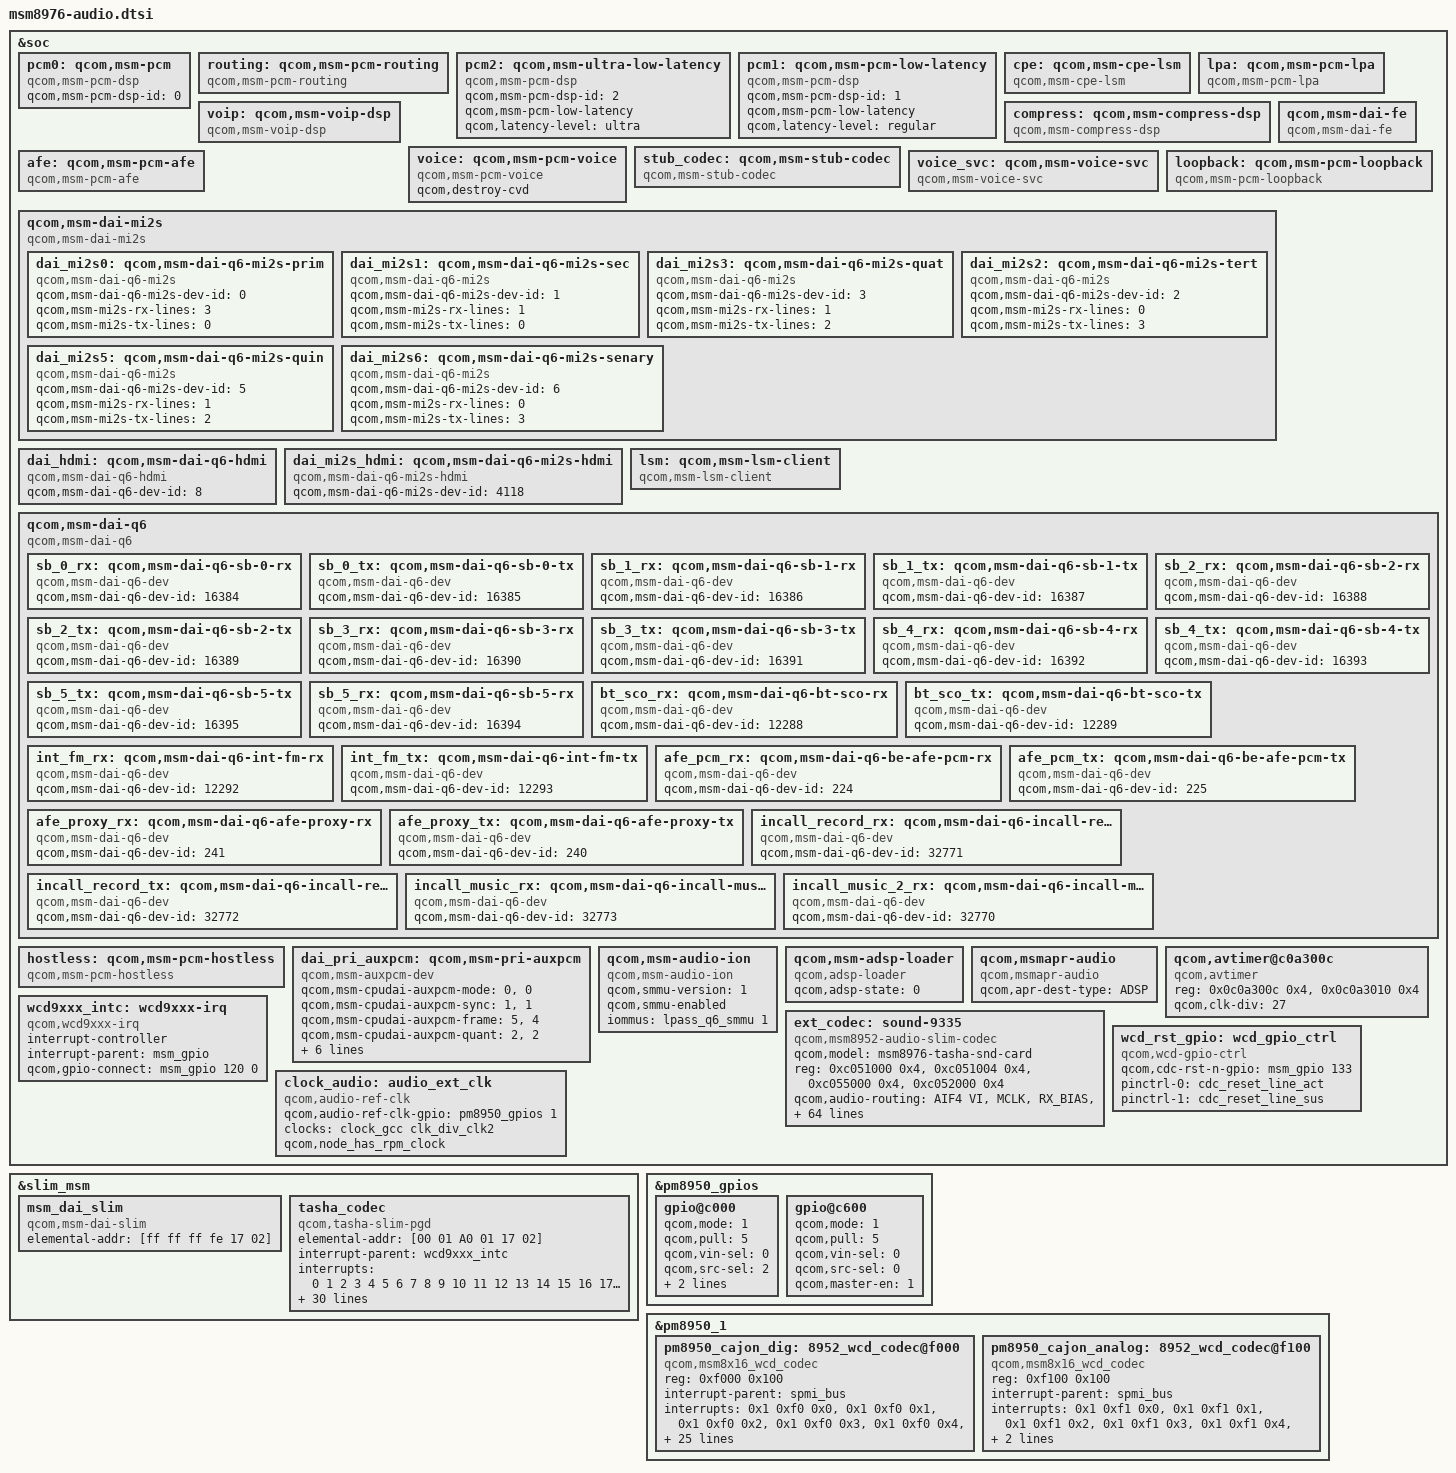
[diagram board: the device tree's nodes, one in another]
/*
 * Copyright (c) 2015-2016, The Linux Foundation. All rights reserved.
 *
 * This program is free software; you can redistribute it and/or modify
 * it under the terms of the GNU General Public License version 2 and
 * only version 2 as published by the Free Software Foundation.
 *
 * This program is distributed in the hope that it will be useful,
 * but WITHOUT ANY WARRANTY; without even the implied warranty of
 * MERCHANTABILITY or FITNESS FOR A PARTICULAR PURPOSE.  See the
 * GNU General Public License for more details.
 */

#include "msm8976-wsa881x.dtsi"

&soc {
	pcm0: qcom,msm-pcm {
		compatible = "qcom,msm-pcm-dsp";
		qcom,msm-pcm-dsp-id = <0>;
	};

	routing: qcom,msm-pcm-routing {
		compatible = "qcom,msm-pcm-routing";
	};

	pcm2: qcom,msm-ultra-low-latency {
		compatible = "qcom,msm-pcm-dsp";
		qcom,msm-pcm-dsp-id = <2>;
		qcom,msm-pcm-low-latency;
		qcom,latency-level = "ultra";
	};

	pcm1: qcom,msm-pcm-low-latency {
		compatible = "qcom,msm-pcm-dsp";
		qcom,msm-pcm-dsp-id = <1>;
		qcom,msm-pcm-low-latency;
		qcom,latency-level = "regular";
	};

	pcm2: qcom,msm-ultra-low-latency {
		compatible = "qcom,msm-pcm-dsp";
		qcom,msm-pcm-dsp-id = <2>;
		qcom,msm-pcm-low-latency;
		qcom,latency-level = "ultra";
	};

	cpe: qcom,msm-cpe-lsm {
		compatible = "qcom,msm-cpe-lsm";
	};

	lpa: qcom,msm-pcm-lpa {
		compatible = "qcom,msm-pcm-lpa";
	};

	compress: qcom,msm-compress-dsp {
		compatible = "qcom,msm-compress-dsp";
	};

	voip: qcom,msm-voip-dsp {
		compatible = "qcom,msm-voip-dsp";
	};

	voice: qcom,msm-pcm-voice {
		compatible = "qcom,msm-pcm-voice";
		qcom,destroy-cvd;
	};

	stub_codec: qcom,msm-stub-codec {
		compatible = "qcom,msm-stub-codec";
	};

	qcom,msm-dai-fe {
		compatible = "qcom,msm-dai-fe";
	};

	afe: qcom,msm-pcm-afe {
		compatible = "qcom,msm-pcm-afe";
	};

	voice_svc: qcom,msm-voice-svc {
		compatible = "qcom,msm-voice-svc";
	};

	loopback: qcom,msm-pcm-loopback {
		compatible = "qcom,msm-pcm-loopback";
	};

	qcom,msm-dai-mi2s {
		compatible = "qcom,msm-dai-mi2s";
		dai_mi2s0: qcom,msm-dai-q6-mi2s-prim {
			compatible = "qcom,msm-dai-q6-mi2s";
			qcom,msm-dai-q6-mi2s-dev-id = <0>;
			qcom,msm-mi2s-rx-lines = <3>;
			qcom,msm-mi2s-tx-lines = <0>;
		};

		dai_mi2s1: qcom,msm-dai-q6-mi2s-sec {
			compatible = "qcom,msm-dai-q6-mi2s";
			qcom,msm-dai-q6-mi2s-dev-id = <1>;
			qcom,msm-mi2s-rx-lines = <1>;
			qcom,msm-mi2s-tx-lines = <0>;
		};

		dai_mi2s3: qcom,msm-dai-q6-mi2s-quat {
			compatible = "qcom,msm-dai-q6-mi2s";
			qcom,msm-dai-q6-mi2s-dev-id = <3>;
			qcom,msm-mi2s-rx-lines = <1>;
			qcom,msm-mi2s-tx-lines = <2>;
		};

		dai_mi2s2: qcom,msm-dai-q6-mi2s-tert {
			compatible = "qcom,msm-dai-q6-mi2s";
			qcom,msm-dai-q6-mi2s-dev-id = <2>;
			qcom,msm-mi2s-rx-lines = <0>;
			qcom,msm-mi2s-tx-lines = <3>;
		};

		dai_mi2s5: qcom,msm-dai-q6-mi2s-quin {
			compatible = "qcom,msm-dai-q6-mi2s";
			qcom,msm-dai-q6-mi2s-dev-id = <5>;
			qcom,msm-mi2s-rx-lines = <1>;
			qcom,msm-mi2s-tx-lines = <2>;
		};

		dai_mi2s6: qcom,msm-dai-q6-mi2s-senary {
			compatible = "qcom,msm-dai-q6-mi2s";
			qcom,msm-dai-q6-mi2s-dev-id = <6>;
			qcom,msm-mi2s-rx-lines = <0>;
			qcom,msm-mi2s-tx-lines = <3>;
		};
	};

	dai_hdmi: qcom,msm-dai-q6-hdmi {
		compatible = "qcom,msm-dai-q6-hdmi";
		qcom,msm-dai-q6-dev-id = <8>;
	};

	dai_mi2s_hdmi: qcom,msm-dai-q6-mi2s-hdmi {
		compatible = "qcom,msm-dai-q6-mi2s-hdmi";
		qcom,msm-dai-q6-mi2s-dev-id = <4118>;
	};

	lsm: qcom,msm-lsm-client {
		compatible = "qcom,msm-lsm-client";
	};

	qcom,msm-dai-q6 {
		compatible = "qcom,msm-dai-q6";
		sb_0_rx: qcom,msm-dai-q6-sb-0-rx {
			compatible = "qcom,msm-dai-q6-dev";
			qcom,msm-dai-q6-dev-id = <16384>;
		};

		sb_0_tx: qcom,msm-dai-q6-sb-0-tx {
			compatible = "qcom,msm-dai-q6-dev";
			qcom,msm-dai-q6-dev-id = <16385>;
		};

		sb_1_rx: qcom,msm-dai-q6-sb-1-rx {
			compatible = "qcom,msm-dai-q6-dev";
			qcom,msm-dai-q6-dev-id = <16386>;
		};

		sb_1_tx: qcom,msm-dai-q6-sb-1-tx {
			compatible = "qcom,msm-dai-q6-dev";
			qcom,msm-dai-q6-dev-id = <16387>;
		};

		sb_2_rx: qcom,msm-dai-q6-sb-2-rx {
			compatible = "qcom,msm-dai-q6-dev";
			qcom,msm-dai-q6-dev-id = <16388>;
		};

		sb_2_tx: qcom,msm-dai-q6-sb-2-tx {
			compatible = "qcom,msm-dai-q6-dev";
			qcom,msm-dai-q6-dev-id = <16389>;
		};


		sb_3_rx: qcom,msm-dai-q6-sb-3-rx {
			compatible = "qcom,msm-dai-q6-dev";
			qcom,msm-dai-q6-dev-id = <16390>;
		};

		sb_3_tx: qcom,msm-dai-q6-sb-3-tx {
			compatible = "qcom,msm-dai-q6-dev";
			qcom,msm-dai-q6-dev-id = <16391>;
		};

		sb_4_rx: qcom,msm-dai-q6-sb-4-rx {
			compatible = "qcom,msm-dai-q6-dev";
			qcom,msm-dai-q6-dev-id = <16392>;
		};

		sb_4_tx: qcom,msm-dai-q6-sb-4-tx {
			compatible = "qcom,msm-dai-q6-dev";
			qcom,msm-dai-q6-dev-id = <16393>;
		};

		sb_5_tx: qcom,msm-dai-q6-sb-5-tx {
			compatible = "qcom,msm-dai-q6-dev";
			qcom,msm-dai-q6-dev-id = <16395>;
		};

		sb_5_rx: qcom,msm-dai-q6-sb-5-rx {
			compatible = "qcom,msm-dai-q6-dev";
			qcom,msm-dai-q6-dev-id = <16394>;
		};

		bt_sco_rx: qcom,msm-dai-q6-bt-sco-rx {
			compatible = "qcom,msm-dai-q6-dev";
			qcom,msm-dai-q6-dev-id = <12288>;
		};

		bt_sco_tx: qcom,msm-dai-q6-bt-sco-tx {
			compatible = "qcom,msm-dai-q6-dev";
			qcom,msm-dai-q6-dev-id = <12289>;
		};

		int_fm_rx: qcom,msm-dai-q6-int-fm-rx {
			compatible = "qcom,msm-dai-q6-dev";
			qcom,msm-dai-q6-dev-id = <12292>;
		};

		int_fm_tx: qcom,msm-dai-q6-int-fm-tx {
			compatible = "qcom,msm-dai-q6-dev";
			qcom,msm-dai-q6-dev-id = <12293>;
		};

		afe_pcm_rx: qcom,msm-dai-q6-be-afe-pcm-rx {
			compatible = "qcom,msm-dai-q6-dev";
			qcom,msm-dai-q6-dev-id = <224>;
		};

		afe_pcm_tx: qcom,msm-dai-q6-be-afe-pcm-tx {
			compatible = "qcom,msm-dai-q6-dev";
			qcom,msm-dai-q6-dev-id = <225>;
		};

		afe_proxy_rx: qcom,msm-dai-q6-afe-proxy-rx {
			compatible = "qcom,msm-dai-q6-dev";
			qcom,msm-dai-q6-dev-id = <241>;
		};

		afe_proxy_tx: qcom,msm-dai-q6-afe-proxy-tx {
			compatible = "qcom,msm-dai-q6-dev";
			qcom,msm-dai-q6-dev-id = <240>;
		};

		incall_record_rx: qcom,msm-dai-q6-incall-record-rx {
			compatible = "qcom,msm-dai-q6-dev";
			qcom,msm-dai-q6-dev-id = <32771>;
		};

		incall_record_tx: qcom,msm-dai-q6-incall-record-tx {
			compatible = "qcom,msm-dai-q6-dev";
			qcom,msm-dai-q6-dev-id = <32772>;
		};

		incall_music_rx: qcom,msm-dai-q6-incall-music-rx {
			compatible = "qcom,msm-dai-q6-dev";
			qcom,msm-dai-q6-dev-id = <32773>;
		};

		incall_music_2_rx: qcom,msm-dai-q6-incall-music-2-rx {
			compatible = "qcom,msm-dai-q6-dev";
			qcom,msm-dai-q6-dev-id = <32770>;
		};
	};

	hostless: qcom,msm-pcm-hostless {
		compatible = "qcom,msm-pcm-hostless";
	};

	dai_pri_auxpcm: qcom,msm-pri-auxpcm {
		compatible = "qcom,msm-auxpcm-dev";
		qcom,msm-cpudai-auxpcm-mode = <0>, <0>;
		qcom,msm-cpudai-auxpcm-sync = <1>, <1>;
		qcom,msm-cpudai-auxpcm-frame = <5>, <4>;
		qcom,msm-cpudai-auxpcm-quant = <2>, <2>;
		qcom,msm-cpudai-auxpcm-num-slots = <1>, <1>;
		qcom,msm-cpudai-auxpcm-slot-mapping = <1>, <1>;
		qcom,msm-cpudai-auxpcm-data = <0>, <0>;
		qcom,msm-cpudai-auxpcm-pcm-clk-rate = <2048000>, <2048000>;
		qcom,msm-auxpcm-interface = "primary";
	};

	qcom,msm-audio-ion {
		compatible = "qcom,msm-audio-ion";
		qcom,smmu-version = <1>;
		qcom,smmu-enabled;
		iommus = <&lpass_q6_smmu 1>;
	};

	qcom,msm-adsp-loader {
		compatible = "qcom,adsp-loader";
		qcom,adsp-state = <0>;
	};

	qcom,msmapr-audio {
		compatible = "qcom,msmapr-audio";
		qcom,apr-dest-type = "ADSP";
	};

	qcom,avtimer@c0a300c {
		compatible = "qcom,avtimer";
		reg = <0x0c0a300c 0x4>,
			<0x0c0a3010 0x4>;
		reg-names = "avtimer_lsb_addr", "avtimer_msb_addr";
		qcom,clk-div = <27>;
	};

	ext_codec: sound-9335 {
		compatible = "qcom,msm8952-audio-slim-codec";
		qcom,model = "msm8976-tasha-snd-card";

		reg = <0xc051000 0x4>,
		    <0xc051004 0x4>,
		    <0xc055000 0x4>,
		    <0xc052000 0x4>;

		reg-names = "csr_gp_io_mux_mic_ctl",
			"csr_gp_io_mux_spkr_ctl",
			"csr_gp_io_lpaif_pri_pcm_pri_mode_muxsel",
			"csr_gp_io_mux_quin_ctl";

		qcom,audio-routing =
			"AIF4 VI", "MCLK",
			"RX_BIAS", "MCLK",
			"MADINPUT", "MCLK",
			"AMIC2", "MIC BIAS2",
			"MIC BIAS2", "Headset Mic",
			"AMIC3", "MIC BIAS2",
			"MIC BIAS2", "ANCRight Headset Mic",
			"AMIC4", "MIC BIAS2",
			"MIC BIAS2", "ANCLeft Headset Mic",
			"AMIC5", "MIC BIAS3",
			"MIC BIAS3", "Handset Mic",
			"AMIC6", "MIC BIAS4",
			"MIC BIAS4", "Analog Mic6",
			"DMIC0", "MIC BIAS1",
			"MIC BIAS1", "Digital Mic0",
			"DMIC1", "MIC BIAS1",
			"MIC BIAS1", "Digital Mic1",
			"DMIC2", "MIC BIAS3",
			"MIC BIAS3", "Digital Mic2",
			"DMIC3", "MIC BIAS3",
			"MIC BIAS3", "Digital Mic3",
			"DMIC4", "MIC BIAS4",
			"MIC BIAS4", "Digital Mic4",
			"DMIC5", "MIC BIAS4",
			"MIC BIAS4", "Digital Mic5",
			"SpkrLeft IN", "SPK1 OUT",
			"SpkrRight IN", "SPK2 OUT";

		qcom,msm-gpios =
			"us_eu_gpio";
		qcom,pinctrl-names =
			"all_off",
			"us_eu_gpio_act";
		pinctrl-names =
			"all_off",
			"us_eu_gpio_act";
		pinctrl-0 = <&cross_conn_det_sus>;
		pinctrl-1 = <&cross_conn_det_act>;
		qcom,cdc-us-euro-gpios = <&msm_gpio 144 0>;

		qcom,msm-mbhc-hphl-swh = <0>;
		qcom,msm-mbhc-gnd-swh = <0>;
		qcom,tasha-mclk-clk-freq = <9600000>;
		asoc-platform = <&pcm0>, <&pcm1>, <&pcm2>, <&voip>, <&voice>,
				<&loopback>, <&compress>, <&hostless>,
				<&afe>, <&lsm>, <&routing>, <&cpe>, <&lpa>;
		asoc-platform-names = "msm-pcm-dsp.0", "msm-pcm-dsp.1", "msm-pcm-dsp.2",
				"msm-voip-dsp", "msm-pcm-voice", "msm-pcm-loopback",
				"msm-compress-dsp", "msm-pcm-hostless", "msm-pcm-afe",
				"msm-lsm-client", "msm-pcm-routing", "msm-cpe-lsm",
				"msm-pcm-lpa";
		asoc-cpu = <&dai_pri_auxpcm>, <&dai_hdmi>, <&dai_mi2s_hdmi>,
				<&dai_mi2s2>, <&dai_mi2s3>, <&dai_mi2s5>,
				<&sb_0_rx>, <&sb_0_tx>, <&sb_1_rx>, <&sb_1_tx>,
				<&sb_2_rx>, <&sb_2_tx>, <&sb_3_rx>, <&sb_3_tx>,
				<&sb_4_rx>, <&sb_4_tx>, <&sb_5_tx>, <&afe_pcm_rx>,
				<&afe_pcm_tx>, <&afe_proxy_rx>, <&afe_proxy_tx>,
				<&incall_record_rx>, <&incall_record_tx>,
				<&incall_music_rx>, <&incall_music_2_rx>,
				<&sb_5_rx>,  <&bt_sco_rx>,
				<&bt_sco_tx>, <&int_fm_rx>, <&int_fm_tx>;
		asoc-cpu-names = "msm-dai-q6-auxpcm.1",	"msm-dai-q6-hdmi.8",
				"msm-dai-q6-mi2s-hdmi.4118",
				"msm-dai-q6-mi2s.2",
				"msm-dai-q6-mi2s.3", "msm-dai-q6-mi2s.5",
				"msm-dai-q6-dev.16384", "msm-dai-q6-dev.16385",
				"msm-dai-q6-dev.16386", "msm-dai-q6-dev.16387",
				"msm-dai-q6-dev.16388", "msm-dai-q6-dev.16389",
				"msm-dai-q6-dev.16390", "msm-dai-q6-dev.16391",
				"msm-dai-q6-dev.16392", "msm-dai-q6-dev.16393",
				"msm-dai-q6-dev.16395", "msm-dai-q6-dev.224",
				"msm-dai-q6-dev.225", "msm-dai-q6-dev.241",
				"msm-dai-q6-dev.240", "msm-dai-q6-dev.32771",
				"msm-dai-q6-dev.32772", "msm-dai-q6-dev.32773",
				"msm-dai-q6-dev.32770", "msm-dai-q6-dev.16394",
				"msm-dai-q6-dev.12288", "msm-dai-q6-dev.12289",
				"msm-dai-q6-dev.12292", "msm-dai-q6-dev.12293";
		asoc-codec = <&stub_codec>;
		asoc-codec-names = "msm-stub-codec.1";
		qcom,wsa-max-devs = <2>;
		qcom,wsa-devs = <&wsa881x_211>, <&wsa881x_212>,
				<&wsa881x_213>, <&wsa881x_214>;
		qcom,wsa-aux-dev-prefix = "SpkrLeft", "SpkrRight",
					"SpkrLeft", "SpkrRight";
	};

	wcd9xxx_intc: wcd9xxx-irq {
		compatible = "qcom,wcd9xxx-irq";
		interrupt-controller;
		#interrupt-cells = <1>;
		interrupt-parent = <&msm_gpio>;
		qcom,gpio-connect = <&msm_gpio 120 0>;
	};

	wcd_rst_gpio: wcd_gpio_ctrl {
		compatible = "qcom,wcd-gpio-ctrl";
		qcom,cdc-rst-n-gpio = <&msm_gpio 133 0>;
		pinctrl-names = "aud_active", "aud_sleep";
		pinctrl-0 = <&cdc_reset_line_act>;
		pinctrl-1 = <&cdc_reset_line_sus>;
	};

	clock_audio: audio_ext_clk {
		compatible = "qcom,audio-ref-clk";
		qcom,audio-ref-clk-gpio = <&pm8950_gpios 1 0>;
		clock-names = "osr_clk";
		clocks = <&clock_gcc clk_div_clk2>;
		qcom,node_has_rpm_clock;
		#clock-cells = <1>;
	};
};

&slim_msm {
	msm_dai_slim {
		compatible = "qcom,msm-dai-slim";
		elemental-addr = [ff ff ff fe 17 02];
	};

	tasha_codec {
		compatible = "qcom,tasha-slim-pgd";
		elemental-addr = [00 01 A0 01 17 02];

		interrupt-parent = <&wcd9xxx_intc>;
		interrupts = <0 1 2 3 4 5 6 7 8 9 10 11 12 13 14 15 16
			17 18 19 20 21 22 23 24 25 26 27 28 29
			30>;

		cdc-vdd-buck-supply = <&eldo2_8976>;
		qcom,cdc-vdd-buck-voltage = <1800000 1800000>;
		qcom,cdc-vdd-buck-current = <650000>;

		cdc-buck-sido-supply = <&eldo2_8976>;
		qcom,cdc-buck-sido-voltage = <1800000 1800000>;
		qcom,cdc-buck-sido-current = <250000>;
		cdc-vdd-tx-h-supply = <&pm8950_l5>;
		qcom,cdc-vdd-tx-h-voltage = <1800000 1800000>;
		qcom,cdc-vdd-tx-h-current = <25000>;

		cdc-vdd-rx-h-supply = <&pm8950_l5>;
		qcom,cdc-vdd-rx-h-voltage = <1800000 1800000>;
		qcom,cdc-vdd-rx-h-current = <25000>;

		cdc-vdd-px-supply = <&pm8950_l5>;
		qcom,cdc-vdd-px-voltage = <1800000 1800000>;
		qcom,cdc-vdd-px-current = <10000>;

		qcom,cdc-static-supplies =
			"cdc-vdd-buck",
			"cdc-buck-sido",
			"cdc-vdd-tx-h",
			"cdc-vdd-rx-h",
			"cdc-vdd-px";

		qcom,cdc-micbias1-mv = <1800>;
		qcom,cdc-micbias2-mv = <1800>;
		qcom,cdc-micbias3-mv = <1800>;
		qcom,cdc-micbias4-mv = <1800>;

		qcom,cdc-mclk-clk-rate = <9600000>;
		qcom,cdc-slim-ifd = "tasha-slim-ifd";
		qcom,cdc-slim-ifd-elemental-addr = [00 00 A0 01 17 02];
		qcom,cdc-dmic-sample-rate = <4800000>;
		qcom,cdc-mad-dmic-rate = <600000>;

		clock-names = "wcd_clk";
		clocks = <&clock_audio clk_audio_pmi_clk>;
		qcom,wcd-rst-gpio-node = <&wcd_rst_gpio>;
	};
};

&pm8950_gpios {
	gpio@c000 {
		status = "ok";
		qcom,mode = <1>;
		qcom,pull = <5>;
		qcom,vin-sel = <0>;
		qcom,src-sel = <2>;
		qcom,master-en = <1>;
		qcom,out-strength = <2>;
	};
	gpio@c600 {
		status = "ok";
		qcom,mode = <1>;
		qcom,pull = <5>;
		qcom,vin-sel = <0>;
		qcom,src-sel = <0>;
		qcom,master-en = <1>;
	};
};

&pm8950_1 {
	pm8950_cajon_dig: 8952_wcd_codec@f000 {
		compatible = "qcom,msm8x16_wcd_codec";
		reg = <0xf000 0x100>;
		interrupt-parent = <&spmi_bus>;
		interrupts = <0x1 0xf0 0x0>,
			     <0x1 0xf0 0x1>,
			     <0x1 0xf0 0x2>,
			     <0x1 0xf0 0x3>,
			     <0x1 0xf0 0x4>,
			     <0x1 0xf0 0x5>,
			     <0x1 0xf0 0x6>,
			     <0x1 0xf0 0x7>;
		interrupt-names = "spk_cnp_int",
				  "spk_clip_int",
				  "spk_ocp_int",
				  "ins_rem_det1",
				  "but_rel_det",
				  "but_press_det",
				  "ins_rem_det",
				  "mbhc_int";

		cdc-vdda-cp-supply = <&pm8950_s4>;
		qcom,cdc-vdda-cp-voltage = <2050000 2050000>;
		qcom,cdc-vdda-cp-current = <500000>;

		cdc-vdda-rx-h-supply = <&pm8950_l5>;
		qcom,cdc-vdda-rx-h-voltage = <1800000 1800000>;
		qcom,cdc-vdda-rx-h-current = <5000>;

		cdc-vdda-tx-h-supply = <&pm8950_l5>;
		qcom,cdc-vdda-tx-h-voltage = <1800000 1800000>;
		qcom,cdc-vdda-tx-h-current = <5000>;

		cdc-vdd-px-supply = <&pm8950_l5>;
		qcom,cdc-vdd-px-voltage = <1800000 1800000>;
		qcom,cdc-vdd-px-current = <5000>;

		cdc-vdd-pa-supply = <&pm8950_s4>;
		qcom,cdc-vdd-pa-voltage = <2050000 2050000>;
		qcom,cdc-vdd-pa-current = <260000>;

		cdc-vdd-mic-bias-supply = <&pm8950_l13>;
		qcom,cdc-vdd-mic-bias-voltage = <3075000 3075000>;
		qcom,cdc-vdd-mic-bias-current = <5000>;

		qcom,cdc-mclk-clk-rate = <9600000>;

		qcom,cdc-static-supplies = "cdc-vdda-rx-h",
					   "cdc-vdda-tx-h",
					   "cdc-vdd-px",
					   "cdc-vdd-pa",
					   "cdc-vdda-cp";

		qcom,cdc-on-demand-supplies = "cdc-vdd-mic-bias";
		qcom,dig-cdc-base-addr = <0xc0f0000>;
	};

	pm8950_cajon_analog: 8952_wcd_codec@f100 {
		compatible = "qcom,msm8x16_wcd_codec";
		reg = <0xf100 0x100>;
		interrupt-parent = <&spmi_bus>;
		interrupts = <0x1 0xf1 0x0>,
			     <0x1 0xf1 0x1>,
			     <0x1 0xf1 0x2>,
			     <0x1 0xf1 0x3>,
			     <0x1 0xf1 0x4>,
			     <0x1 0xf1 0x5>;
		interrupt-names = "ear_ocp_int",
				  "hphr_ocp_int",
				  "hphl_ocp_det",
				  "ear_cnp_int",
				  "hphr_cnp_int",
				  "hphl_cnp_int";
		qcom,dig-cdc-base-addr = <0xc0f0000>;
	};
};
